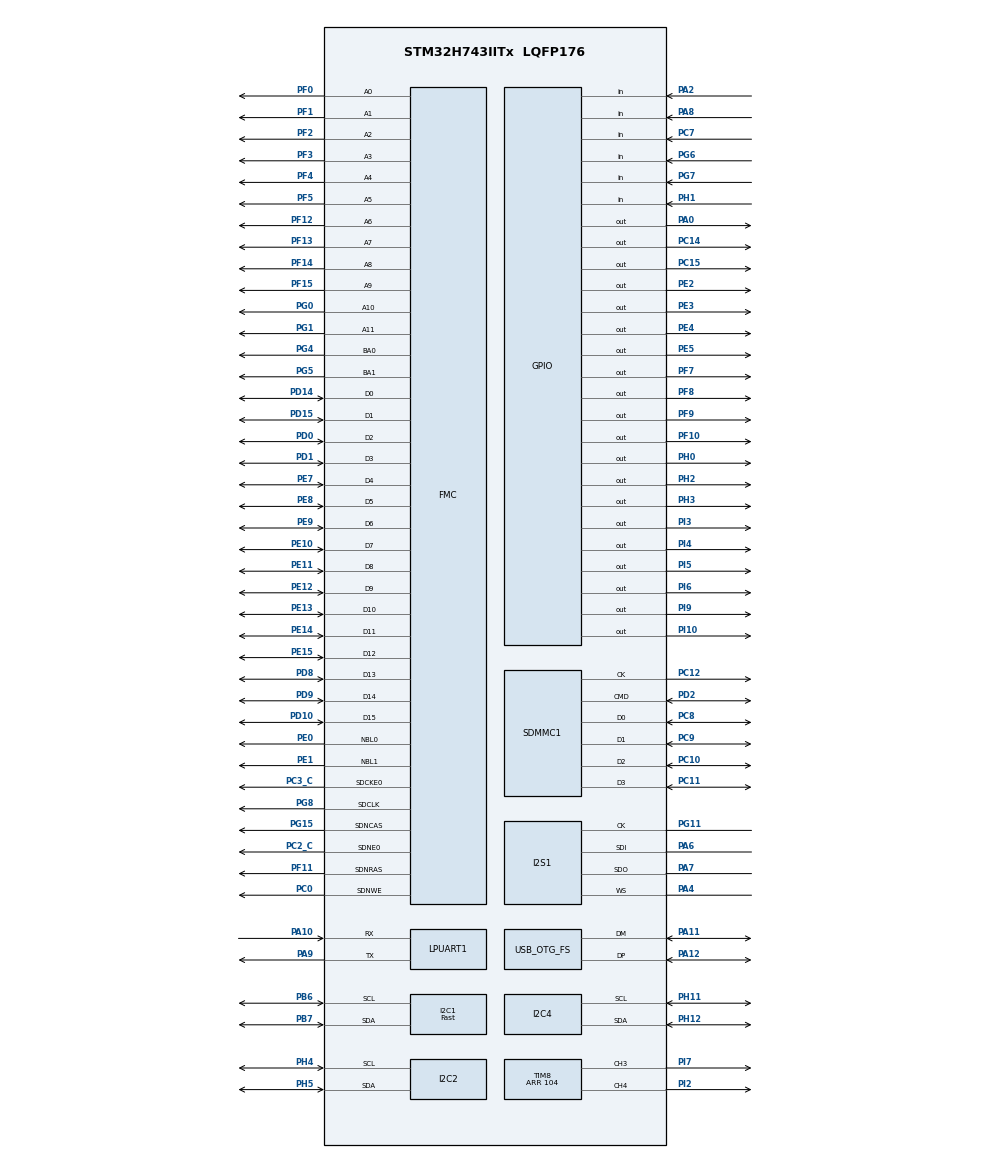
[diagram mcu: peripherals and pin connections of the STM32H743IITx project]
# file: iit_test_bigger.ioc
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CORTEX_M7.default_mode_Activation=1
Dma.Request0=TIM8_CH4
Dma.Request1=TIM8_CH3
Dma.TIM8_CH3.1.Direction=DMA_MEMORY_TO_PERIPH
Dma.TIM8_CH3.1.EventEnable=DISABLE
Dma.TIM8_CH3.1.FIFOMode=DMA_FIFOMODE_DISABLE
Dma.TIM8_CH3.1.Instance=DMA1_Stream1
Dma.TIM8_CH3.1.MemDataAlignment=DMA_MDATAALIGN_HALFWORD
Dma.TIM8_CH3.1.MemInc=DMA_MINC_ENABLE
Dma.TIM8_CH3.1.Mode=DMA_NORMAL
Dma.TIM8_CH3.1.PeriphDataAlignment=DMA_PDATAALIGN_HALFWORD
Dma.TIM8_CH3.1.PeriphInc=DMA_PINC_DISABLE
Dma.TIM8_CH3.1.Polarity=HAL_DMAMUX_REQ_GEN_RISING
Dma.TIM8_CH3.1.Priority=DMA_PRIORITY_HIGH
Dma.TIM8_CH3.1.RequestNumber=1
Dma.TIM8_CH3.1.SignalID=NONE
Dma.TIM8_CH3.1.SyncEnable=DISABLE
Dma.TIM8_CH3.1.SyncPolarity=HAL_DMAMUX_SYNC_NO_EVENT
Dma.TIM8_CH3.1.SyncRequestNumber=1
Dma.TIM8_CH3.1.SyncSignalID=NONE
Dma.TIM8_CH4.0.Direction=DMA_MEMORY_TO_PERIPH
Dma.TIM8_CH4.0.EventEnable=DISABLE
Dma.TIM8_CH4.0.FIFOMode=DMA_FIFOMODE_DISABLE
Dma.TIM8_CH4.0.Instance=DMA1_Stream0
Dma.TIM8_CH4.0.MemDataAlignment=DMA_MDATAALIGN_HALFWORD
Dma.TIM8_CH4.0.MemInc=DMA_MINC_ENABLE
Dma.TIM8_CH4.0.Mode=DMA_NORMAL
Dma.TIM8_CH4.0.PeriphDataAlignment=DMA_PDATAALIGN_HALFWORD
Dma.TIM8_CH4.0.PeriphInc=DMA_PINC_DISABLE
Dma.TIM8_CH4.0.Polarity=HAL_DMAMUX_REQ_GEN_RISING
Dma.TIM8_CH4.0.Priority=DMA_PRIORITY_HIGH
Dma.TIM8_CH4.0.RequestNumber=1
Dma.TIM8_CH4.0.SignalID=NONE
Dma.TIM8_CH4.0.SyncEnable=DISABLE
Dma.TIM8_CH4.0.SyncPolarity=HAL_DMAMUX_SYNC_NO_EVENT
Dma.TIM8_CH4.0.SyncRequestNumber=1
Dma.TIM8_CH4.0.SyncSignalID=NONE
FMC.CASLatency1=FMC_SDRAM_CAS_LATENCY_3
FMC.ColumnBitsNumber1=FMC_SDRAM_COLUMN_BITS_NUM_9
FMC.ExitSelfRefreshDelay1=7
FMC.LoadToActiveDelay1=2
FMC.RCDDelay1=2
FMC.RPDelay1=2
FMC.RPDelay2=2
FMC.ReadBurst1=FMC_SDRAM_RBURST_ENABLE
FMC.ReadPipeDelay1=FMC_SDRAM_RPIPE_DELAY_1
FMC.ReadPipeDelay2=FMC_SDRAM_RPIPE_DELAY_1
FMC.RowCycleDelay1=7
FMC.RowCycleDelay2=7
FMC.SDClockPeriod1=FMC_SDRAM_CLOCK_PERIOD_2
FMC.SelfRefreshTime1=4
FMC.WriteRecoveryTime1=3
I2C1.I2C_Speed_Mode=I2C_Fast
I2C1.Timing=0x00300F38
I2C2.Timing=0x00707CBB
I2C4.Timing=0x00707CBB
I2S1.ErrorAudioFreq=-0.16 %
I2S1.Instance=SPI$Index
I2S1.RealAudioFreq=7.987 KHz
Mcu.Family=STM32H7
Mcu.Name=STM32H743IITx
Mcu.Package=LQFP176
NVIC.DMA1_Stream0_IRQn=true\:0\:0\:false\:false\:true\:false\:true\:true
NVIC.DMA1_Stream1_IRQn=true\:0\:0\:false\:false\:true\:false\:true\:true
NVIC.OTG_FS_IRQn=true\:0\:0\:false\:false\:true\:true\:true\:true
NVIC.PriorityGroup=NVIC_PRIORITYGROUP_4
PA0.Signal=GPIO_Output
PA10.Mode=Asynchronous
PA10.Signal=LPUART1_RX
PA11.Mode=Device_Only
PA11.Signal=USB_OTG_FS_DM
PA12.Mode=Device_Only
PA12.Signal=USB_OTG_FS_DP
PA13\ (JTMS/SWDIO).Mode=Serial_Wire
PA13\ (JTMS/SWDIO).Signal=DEBUG_JTMS-SWDIO
PA14\ (JTCK/SWCLK).Mode=Serial_Wire
PA14\ (JTCK/SWCLK).Signal=DEBUG_JTCK-SWCLK
PA15\ (JTDI).Signal=DEBUG_JTDI
PA2.Signal=GPIO_Input
PA4.Mode=Full_Duplex_Master
PA4.Signal=I2S1_WS
PA6.Mode=Full_Duplex_Master
PA6.Signal=I2S1_SDI
PA7.Mode=Full_Duplex_Master
PA7.Signal=I2S1_SDO
PA8.Signal=GPIO_Input
PA9.Mode=Asynchronous
PA9.Signal=LPUART1_TX
PB3\ (JTDO/TRACESWO).Signal=DEBUG_JTDO-SWO
PB6.Mode=I2C
PB6.Signal=I2C1_SCL
PB7.Mode=I2C
PB7.Signal=I2C1_SDA
PC0.Signal=FMC_SDNWE
PC10.Mode=SD_4_bits_Wide_bus
PC10.Signal=SDMMC1_D2
PC11.Mode=SD_4_bits_Wide_bus
PC11.Signal=SDMMC1_D3
PC12.Mode=SD_4_bits_Wide_bus
PC12.Signal=SDMMC1_CK
PC14-OSC32_IN\ (OSC32_IN).Signal=GPIO_Output
PC15-OSC32_OUT\ (OSC32_OUT).Signal=GPIO_Output
PC2_C.Mode=SdramChipSelect1_1
PC2_C.Signal=FMC_SDNE0
PC3_C.Mode=SdramChipSelect1_1
PC3_C.Signal=FMC_SDCKE0
PC7.Signal=GPIO_Input
PC8.Mode=SD_4_bits_Wide_bus
PC8.Signal=SDMMC1_D0
PC9.Mode=SD_4_bits_Wide_bus
PC9.Signal=SDMMC1_D1
PD0.Signal=FMC_D2_DA2
PD1.Signal=FMC_D3_DA3
PD10.Signal=FMC_D15_DA15
PD14.Signal=FMC_D0_DA0
PD15.Signal=FMC_D1_DA1
PD2.Mode=SD_4_bits_Wide_bus
PD2.Signal=SDMMC1_CMD
PD8.Signal=FMC_D13_DA13
PD9.Signal=FMC_D14_DA14
PE0.Signal=FMC_NBL0
PE1.Signal=FMC_NBL1
PE10.Signal=FMC_D7_DA7
PE11.Signal=FMC_D8_DA8
PE12.Signal=FMC_D9_DA9
PE13.Signal=FMC_D10_DA10
PE14.Signal=FMC_D11_DA11
PE15.Signal=FMC_D12_DA12
PE2.Signal=GPIO_Output
PE3.Signal=GPIO_Output
PE4.Signal=GPIO_Output
PE5.Signal=GPIO_Output
PE7.Signal=FMC_D4_DA4
PE8.Signal=FMC_D5_DA5
PE9.Signal=FMC_D6_DA6
PF0.Signal=FMC_A0
PF1.Signal=FMC_A1
PF10.Signal=GPIO_Output
PF11.Signal=FMC_SDNRAS
PF12.Signal=FMC_A6
PF13.Signal=FMC_A7
PF14.Signal=FMC_A8
PF15.Signal=FMC_A9
PF2.Signal=FMC_A2
PF3.Signal=FMC_A3
PF4.Signal=FMC_A4
PF5.Signal=FMC_A5
PF7.Signal=GPIO_Output
PF8.Signal=GPIO_Output
PF9.Signal=GPIO_Output
PG0.Signal=FMC_A10
PG1.Signal=FMC_A11
PG11.Mode=Full_Duplex_Master
PG11.Signal=I2S1_CK
PG15.Signal=FMC_SDNCAS
PG4.Signal=FMC_A14_BA0
PG5.Signal=FMC_A15_BA1
PG6.Signal=GPIO_Input
PG7.Signal=GPIO_Input
PG8.Signal=FMC_SDCLK
PH0-OSC_IN\ (PH0).Signal=GPIO_Output
PH1-OSC_OUT\ (PH1).Signal=GPIO_Input
PH11.Mode=I2C
PH11.Signal=I2C4_SCL
PH12.Mode=I2C
PH12.Signal=I2C4_SDA
PH2.Signal=GPIO_Output
PH3.Signal=GPIO_Output
PH4.Mode=I2C
PH4.Signal=I2C2_SCL
PH5.Mode=I2C
PH5.Signal=I2C2_SDA
PI10.Signal=GPIO_Output
PI2.Signal=S_TIM8_CH4
PI3.Signal=GPIO_Output
PI4.Signal=GPIO_Output
PI5.Signal=GPIO_Output
PI6.Signal=GPIO_Output
PI7.Signal=S_TIM8_CH3
PI9.Signal=GPIO_Output
ProjectManager.HeapSize=0x200
ProjectManager.StackSize=0x400
ProjectManager.TargetToolchain=CMake
RCC.ADCFreq_Value=128000000
RCC.APB1Freq_Value=32000000
RCC.APB2Freq_Value=64000000
RCC.APB3Freq_Value=32000000
RCC.APB4Freq_Value=32000000
RCC.CortexFreq_Value=64000000
RCC.D1PPRE=RCC_APB3_DIV2
RCC.D2PPRE1=RCC_APB1_DIV2
RCC.D3PPRE=RCC_APB4_DIV2
RCC.DIVM1=4
RCC.DIVM2=4
RCC.DIVN1=25
RCC.DIVN2=16
RCC.DIVQ1=5
RCC.FMCCLockSelection=RCC_FMCCLKSOURCE_PLL2
RCC.HCLKFreq_Value=64000000
RCC.SYSCLKFreq_VALUE=64000000
RCC.USBCLockSelection=RCC_USBCLKSOURCE_HSI48
RCC.USBFreq_Value=48000000
SDMMC1.ClockDiv=2
SH.FMC_A0.0=FMC_A0,12b-sda1
SH.FMC_A1.0=FMC_A1,12b-sda1
SH.FMC_A10.0=FMC_A10,12b-sda1
SH.FMC_A11.0=FMC_A11,12b-sda1
SH.FMC_A14_BA0.0=FMC_BA0,FourSdramBanks1
SH.FMC_A15_BA1.0=FMC_BA1,FourSdramBanks1
SH.FMC_A2.0=FMC_A2,12b-sda1
SH.FMC_A3.0=FMC_A3,12b-sda1
SH.FMC_A4.0=FMC_A4,12b-sda1
SH.FMC_A5.0=FMC_A5,12b-sda1
SH.FMC_A6.0=FMC_A6,12b-sda1
SH.FMC_A7.0=FMC_A7,12b-sda1
SH.FMC_A8.0=FMC_A8,12b-sda1
SH.FMC_A9.0=FMC_A9,12b-sda1
SH.FMC_D0_DA0.0=FMC_D0,sd-16b-d1
SH.FMC_D10_DA10.0=FMC_D10,sd-16b-d1
SH.FMC_D11_DA11.0=FMC_D11,sd-16b-d1
SH.FMC_D12_DA12.0=FMC_D12,sd-16b-d1
SH.FMC_D13_DA13.0=FMC_D13,sd-16b-d1
SH.FMC_D14_DA14.0=FMC_D14,sd-16b-d1
SH.FMC_D15_DA15.0=FMC_D15,sd-16b-d1
SH.FMC_D1_DA1.0=FMC_D1,sd-16b-d1
SH.FMC_D2_DA2.0=FMC_D2,sd-16b-d1
SH.FMC_D3_DA3.0=FMC_D3,sd-16b-d1
SH.FMC_D4_DA4.0=FMC_D4,sd-16b-d1
SH.FMC_D5_DA5.0=FMC_D5,sd-16b-d1
SH.FMC_D6_DA6.0=FMC_D6,sd-16b-d1
SH.FMC_D7_DA7.0=FMC_D7,sd-16b-d1
SH.FMC_D8_DA8.0=FMC_D8,sd-16b-d1
SH.FMC_D9_DA9.0=FMC_D9,sd-16b-d1
SH.FMC_NBL0.0=FMC_NBL0,Sd2ByteEnable1
SH.FMC_NBL1.0=FMC_NBL1,Sd2ByteEnable1
SH.FMC_SDCLK.0=FMC_SDCLK,12b-sda1
SH.FMC_SDNCAS.0=FMC_SDNCAS,12b-sda1
SH.FMC_SDNRAS.0=FMC_SDNRAS,12b-sda1
SH.FMC_SDNWE.0=FMC_SDNWE,12b-sda1
SH.S_TIM8_CH3.0=TIM8_CH3,PWM Generation3 CH3
SH.S_TIM8_CH4.0=TIM8_CH4,PWM Generation4 CH4
TIM8.Channel-PWM\ Generation3\ CH3=TIM_CHANNEL_3
TIM8.Channel-PWM\ Generation4\ CH4=TIM_CHANNEL_4
TIM8.Period=104
USB_OTG_FS.VirtualMode=Device_Only
VP_MEMORYMAP_VS_MEMORYMAP.Mode=CurAppReg
board=custom

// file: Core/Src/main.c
/* USER CODE BEGIN Header */
/**
  ******************************************************************************
  * @file           : main.c
  * @brief          : Main program body
  ******************************************************************************
  * @attention
  *
  * Copyright (c) 2026 STMicroelectronics.
  * All rights reserved.
  *
  * This software is licensed under terms that can be found in the LICENSE file
  * in the root directory of this software component.
  * If no LICENSE file comes with this software, it is provided AS-IS.
  *
  ******************************************************************************
  */
/* USER CODE END Header */
#include "main.h"

/* USER CODE BEGIN Includes */

#include <stdbool.h>
#include <stdint.h>
#include <stdio.h>

#include "stm32h7xx_hal.h"
#include "stm32h7xx_hal_gpio.h"

#include "tusb.h"
#include "helper.h"

#include "neopixel32.h"
#include "TMAG5273.h"
#include "button.h"
#include "tmag-helper.h"
#include "rgb-helper.h"
#include "lcd-helper.h"

#include "midi.h"

/* USER CODE END Includes */

I2C_HandleTypeDef hi2c1;
I2C_HandleTypeDef hi2c2;
I2C_HandleTypeDef hi2c4;

I2S_HandleTypeDef hi2s1;

UART_HandleTypeDef hlpuart1;

SD_HandleTypeDef hsd1;

TIM_HandleTypeDef htim8;
DMA_HandleTypeDef hdma_tim8_ch4;
DMA_HandleTypeDef hdma_tim8_ch3;

PCD_HandleTypeDef hpcd_USB_OTG_FS;

SDRAM_HandleTypeDef hsdram1;

/* USER CODE BEGIN PV */
bool getFirstTick = true;
uint32_t firstTick = 0;
bool probe_resting_pos = true;
/* USER CODE END PV */

void SystemClock_Config(void);
static void MPU_Config(void);
static void MX_GPIO_Init(void);
static void MX_DMA_Init(void);
static void MX_FMC_Init(void);
static void MX_I2C1_Init(void);
static void MX_I2C2_Init(void);
static void MX_I2C4_Init(void);
static void MX_SDMMC1_SD_Init(void);
static void MX_I2S1_Init(void);
static void MX_LPUART1_UART_Init(void);
static void MX_TIM8_Init(void);
static void MX_USB_OTG_FS_PCD_Init(void);

/* USER CODE BEGIN 0 */
void tick_service() {
  if (getFirstTick) {
    getFirstTick = false;
    firstTick = HAL_GetTick();
  }

  //create a delay before storing initial sensor data, let them warm up bro
  if (((HAL_GetTick() - firstTick) > 1000) && probe_resting_pos) {
    probe_resting_pos = false;
    storedInitialData = false;
    animate_led_startup = true;
  }

  if (animate_led_startup) {
    tick_led_animation();
  }

  //after ~2 seconds
  if (((HAL_GetTick() - firstTick) > 2000)) {
    if (!trigger_main_screen) {
      trigger_main_screen = true;
      state = MAIN_MENU;
    }

    ui_service_tick();
  }
}
/* USER CODE END 0 */

int main(void)
{

  /* MPU Configuration--------------------------------------------------------*/
  MPU_Config();

  /* MCU Configuration--------------------------------------------------------*/

  /* Reset of all peripherals, Initializes the Flash interface and the Systick. */
  HAL_Init();

  /* Configure the system clock */
  SystemClock_Config();

  /* Initialize all configured peripherals */
  MX_GPIO_Init();
  MX_DMA_Init();
  MX_FMC_Init();
  MX_I2C1_Init();
  MX_I2C2_Init();
  MX_I2C4_Init();
  MX_SDMMC1_SD_Init();
  MX_I2S1_Init();
  MX_LPUART1_UART_Init();
  MX_TIM8_Init();
  MX_USB_OTG_FS_PCD_Init();
  /* USER CODE BEGIN 2 */

  debugtalk("hello world\r\n");

  // init neopixels --------------------------------------------------------------------------------------------------------------------

  //internal
  neopixel_instance_internal.LED_Count = 6;
  neopixel_instance_internal.StartDMA_Call = Start_LED_DMA;

  if (NP32_Init(&neopixel_instance_internal) != 0) {
    debugtalk("bad0\r\n");
    Error_Handler();
  }

  NP32_SetAllLEDs_RGB(&neopixel_instance_internal, color_black);
  NP32_Update(&neopixel_instance_internal);

  //keys
  neopixel_instance_keys.LED_Count = 24;
  neopixel_instance_keys.StartDMA_Call = Start_LED_DMA_KEYS;

  if (NP32_Init(&neopixel_instance_keys) != 0) {
    debugtalk("bad00\r\n");
    Error_Handler();
  }

  NP32_SetAllLEDs_RGB(&neopixel_instance_keys, color_black);
  NP32_Update(&neopixel_instance_keys);

  // init i2c lcd display --------------------------------------------------------------------------------------------------------------
  //scan all addresses on i2c as some lcd modules use random
  uint16_t lcd_address = probe_i2c_addr(&hi2c4);

  if (HAL_I2C_IsDeviceReady(&hi2c4, lcd_address, 3, 100) != HAL_OK) {
    debugtalk("LCD not found\r\n");
  }

  lcd.hi2c = &hi2c4;
  lcd.address = (uint8_t)lcd_address;
  lcd_init(&lcd);
  lcd_clear(&lcd);

  lcd_puts(&lcd, "welcome to");
  lcd_gotoxy(&lcd, 0, 1);
  lcd_puts(&lcd, "mpe32board.");

  // init i2c muxes 4 sensors ----------------------------------------------------------------------------------------------------------
  // set mp-reset on the i2c mux to be high as it is active-low reset input
	HAL_GPIO_WritePin(GPIOI, GPIO_PIN_3, GPIO_PIN_SET);

  uint8_t mret = HAL_I2C_IsDeviceReady(&hi2c1, 0x70 << 1, 3, 5);
  if (mret != HAL_OK) {
    debugtalk("bad mux1");
  }

  uint8_t mret2 = HAL_I2C_IsDeviceReady(&hi2c1, 0x71 << 1, 3, 5);
  if (mret2 != HAL_OK) {
    debugtalk("bad mux2");
  }

  uint8_t mret3 = HAL_I2C_IsDeviceReady(&hi2c1, 0x72 << 1, 3, 5);
  if (mret3 != HAL_OK) {
    debugtalk("bad mux3");
  }

  // disable all i2c channels for a clean slate bruh
	if (i2c_mux_reset(&tca_mux_1) != 0) {
    debugtalk("bad1\r\n");
    NP32_SetLED_RGB(&neopixel_instance_internal, 0, color_red);
    NP32_Update(&neopixel_instance_internal);
	}

  if (i2c_mux_reset(&tca_mux_2) != 0) {
    debugtalk("bad2\r\n");
    NP32_SetLED_RGB(&neopixel_instance_internal, 1, color_red);
    NP32_Update(&neopixel_instance_internal);
	}

  if (i2c_mux_reset(&tca_mux_3) != 0) {
    debugtalk("bad3\r\n");
    NP32_SetLED_RGB(&neopixel_instance_internal, 0, color_blue);
    NP32_Update(&neopixel_instance_internal);
	}

  Init_TMAGS();

  // init mpe32board device settings/config here ----------------------------------------------------------------------------------------

  storedInitialData = false;
  fill_midi_key_arr(24, octave);

  // init device stack for tiny usb!!! https://docs.tinyusb.org/en/latest/integration.html ----------------------------------------------
	tud_cdc_write_clear();

  if (!tusb_init(BOARD_DEVICE_RHPORT_NUM, NULL)) {
    debugtalk("bad4\r\n");
  }

  /* USER CODE END 2 */

  /* Infinite loop */
  while (1)
  {

    /* USER CODE BEGIN 3 */

    tud_task();

    tick_service();

    //gather button data
    // SWITCH HERE BETWEEN DEVELOPMENT AND PRODUCTION ENVIRONMENTS //TODO
    //button_debug_handle();
    button_handle();

    //gather sensor data
    sensor_handle();

    //parse data to midi
    midi_parse();

    NP32_Update(&neopixel_instance_internal);
    NP32_Update(&neopixel_instance_keys);

  }
  /* USER CODE END 3 */
}

void SystemClock_Config(void)
{
  RCC_OscInitTypeDef RCC_OscInitStruct = {0};
  RCC_ClkInitTypeDef RCC_ClkInitStruct = {0};

  /** Supply configuration update enable
  */
  HAL_PWREx_ConfigSupply(PWR_LDO_SUPPLY);

  /** Configure the main internal regulator output voltage
  */
  __HAL_PWR_VOLTAGESCALING_CONFIG(PWR_REGULATOR_VOLTAGE_SCALE3);

  while(!__HAL_PWR_GET_FLAG(PWR_FLAG_VOSRDY)) {}

  /** Initializes the RCC Oscillators according to the specified parameters
  * in the RCC_OscInitTypeDef structure.
  */
  RCC_OscInitStruct.OscillatorType = RCC_OSCILLATORTYPE_HSI48|RCC_OSCILLATORTYPE_HSI;
  RCC_OscInitStruct.HSIState = RCC_HSI_DIV1;
  RCC_OscInitStruct.HSICalibrationValue = RCC_HSICALIBRATION_DEFAULT;
  RCC_OscInitStruct.HSI48State = RCC_HSI48_ON;
  RCC_OscInitStruct.PLL.PLLState = RCC_PLL_ON;
  RCC_OscInitStruct.PLL.PLLSource = RCC_PLLSOURCE_HSI;
  RCC_OscInitStruct.PLL.PLLM = 4;
  RCC_OscInitStruct.PLL.PLLN = 25;
  RCC_OscInitStruct.PLL.PLLP = 2;
  RCC_OscInitStruct.PLL.PLLQ = 5;
  RCC_OscInitStruct.PLL.PLLR = 2;
  RCC_OscInitStruct.PLL.PLLRGE = RCC_PLL1VCIRANGE_3;
  RCC_OscInitStruct.PLL.PLLVCOSEL = RCC_PLL1VCOWIDE;
  RCC_OscInitStruct.PLL.PLLFRACN = 0;
  if (HAL_RCC_OscConfig(&RCC_OscInitStruct) != HAL_OK)
  {
    Error_Handler();
  }

  /** Initializes the CPU, AHB and APB buses clocks
  */
  RCC_ClkInitStruct.ClockType = RCC_CLOCKTYPE_HCLK|RCC_CLOCKTYPE_SYSCLK
                              |RCC_CLOCKTYPE_PCLK1|RCC_CLOCKTYPE_PCLK2
                              |RCC_CLOCKTYPE_D3PCLK1|RCC_CLOCKTYPE_D1PCLK1;
  RCC_ClkInitStruct.SYSCLKSource = RCC_SYSCLKSOURCE_HSI;
  RCC_ClkInitStruct.SYSCLKDivider = RCC_SYSCLK_DIV1;
  RCC_ClkInitStruct.AHBCLKDivider = RCC_HCLK_DIV1;
  RCC_ClkInitStruct.APB3CLKDivider = RCC_APB3_DIV2;
  RCC_ClkInitStruct.APB1CLKDivider = RCC_APB1_DIV2;
  RCC_ClkInitStruct.APB2CLKDivider = RCC_APB2_DIV1;
  RCC_ClkInitStruct.APB4CLKDivider = RCC_APB4_DIV2;

  if (HAL_RCC_ClockConfig(&RCC_ClkInitStruct, FLASH_LATENCY_1) != HAL_OK)
  {
    Error_Handler();
  }
}

static void MX_I2C1_Init(void)
{

  hi2c1.Instance = I2C1;
  hi2c1.Init.Timing = 0x00300F38;
  hi2c1.Init.OwnAddress1 = 0;
  hi2c1.Init.AddressingMode = I2C_ADDRESSINGMODE_7BIT;
  hi2c1.Init.DualAddressMode = I2C_DUALADDRESS_DISABLE;
  hi2c1.Init.OwnAddress2 = 0;
  hi2c1.Init.OwnAddress2Masks = I2C_OA2_NOMASK;
  hi2c1.Init.GeneralCallMode = I2C_GENERALCALL_DISABLE;
  hi2c1.Init.NoStretchMode = I2C_NOSTRETCH_DISABLE;
  if (HAL_I2C_Init(&hi2c1) != HAL_OK)
  {
    Error_Handler();
  }

  /** Configure Analogue filter
  */
  if (HAL_I2CEx_ConfigAnalogFilter(&hi2c1, I2C_ANALOGFILTER_ENABLE) != HAL_OK)
  {
    Error_Handler();
  }

  /** Configure Digital filter
  */
  if (HAL_I2CEx_ConfigDigitalFilter(&hi2c1, 0) != HAL_OK)
  {
    Error_Handler();
  }

}

static void MX_I2C2_Init(void)
{

  hi2c2.Instance = I2C2;
  hi2c2.Init.Timing = 0x00707CBB;
  hi2c2.Init.OwnAddress1 = 0;
  hi2c2.Init.AddressingMode = I2C_ADDRESSINGMODE_7BIT;
  hi2c2.Init.DualAddressMode = I2C_DUALADDRESS_DISABLE;
  hi2c2.Init.OwnAddress2 = 0;
  hi2c2.Init.OwnAddress2Masks = I2C_OA2_NOMASK;
  hi2c2.Init.GeneralCallMode = I2C_GENERALCALL_DISABLE;
  hi2c2.Init.NoStretchMode = I2C_NOSTRETCH_DISABLE;
  if (HAL_I2C_Init(&hi2c2) != HAL_OK)
  {
    Error_Handler();
  }

  /** Configure Analogue filter
  */
  if (HAL_I2CEx_ConfigAnalogFilter(&hi2c2, I2C_ANALOGFILTER_ENABLE) != HAL_OK)
  {
    Error_Handler();
  }

  /** Configure Digital filter
  */
  if (HAL_I2CEx_ConfigDigitalFilter(&hi2c2, 0) != HAL_OK)
  {
    Error_Handler();
  }

}

static void MX_I2C4_Init(void)
{

  hi2c4.Instance = I2C4;
  hi2c4.Init.Timing = 0x00707CBB;
  hi2c4.Init.OwnAddress1 = 0;
  hi2c4.Init.AddressingMode = I2C_ADDRESSINGMODE_7BIT;
  hi2c4.Init.DualAddressMode = I2C_DUALADDRESS_DISABLE;
  hi2c4.Init.OwnAddress2 = 0;
  hi2c4.Init.OwnAddress2Masks = I2C_OA2_NOMASK;
  hi2c4.Init.GeneralCallMode = I2C_GENERALCALL_DISABLE;
  hi2c4.Init.NoStretchMode = I2C_NOSTRETCH_DISABLE;
  if (HAL_I2C_Init(&hi2c4) != HAL_OK)
  {
    Error_Handler();
  }

  /** Configure Analogue filter
  */
  if (HAL_I2CEx_ConfigAnalogFilter(&hi2c4, I2C_ANALOGFILTER_ENABLE) != HAL_OK)
  {
    Error_Handler();
  }

  /** Configure Digital filter
  */
  if (HAL_I2CEx_ConfigDigitalFilter(&hi2c4, 0) != HAL_OK)
  {
    Error_Handler();
  }

}

static void MX_I2S1_Init(void)
{

  hi2s1.Instance = SPI1;
  hi2s1.Init.Mode = I2S_MODE_MASTER_FULLDUPLEX;
  hi2s1.Init.Standard = I2S_STANDARD_PHILIPS;
  hi2s1.Init.DataFormat = I2S_DATAFORMAT_16B;
  hi2s1.Init.MCLKOutput = I2S_MCLKOUTPUT_DISABLE;
  hi2s1.Init.AudioFreq = I2S_AUDIOFREQ_8K;
  hi2s1.Init.CPOL = I2S_CPOL_LOW;
  hi2s1.Init.FirstBit = I2S_FIRSTBIT_MSB;
  hi2s1.Init.WSInversion = I2S_WS_INVERSION_DISABLE;
  hi2s1.Init.Data24BitAlignment = I2S_DATA_24BIT_ALIGNMENT_RIGHT;
  hi2s1.Init.MasterKeepIOState = I2S_MASTER_KEEP_IO_STATE_DISABLE;
  if (HAL_I2S_Init(&hi2s1) != HAL_OK)
  {
    Error_Handler();
  }

}

static void MX_LPUART1_UART_Init(void)
{

  hlpuart1.Instance = LPUART1;
  hlpuart1.Init.BaudRate = 209700;
  hlpuart1.Init.WordLength = UART_WORDLENGTH_8B;
  hlpuart1.Init.StopBits = UART_STOPBITS_1;
  hlpuart1.Init.Parity = UART_PARITY_NONE;
  hlpuart1.Init.Mode = UART_MODE_TX_RX;
  hlpuart1.Init.HwFlowCtl = UART_HWCONTROL_NONE;
  hlpuart1.Init.OneBitSampling = UART_ONE_BIT_SAMPLE_DISABLE;
  hlpuart1.Init.ClockPrescaler = UART_PRESCALER_DIV1;
  hlpuart1.AdvancedInit.AdvFeatureInit = UART_ADVFEATURE_NO_INIT;
  hlpuart1.FifoMode = UART_FIFOMODE_DISABLE;
  if (HAL_UART_Init(&hlpuart1) != HAL_OK)
  {
    Error_Handler();
  }
  if (HAL_UARTEx_SetTxFifoThreshold(&hlpuart1, UART_TXFIFO_THRESHOLD_1_8) != HAL_OK)
  {
    Error_Handler();
  }
  if (HAL_UARTEx_SetRxFifoThreshold(&hlpuart1, UART_RXFIFO_THRESHOLD_1_8) != HAL_OK)
  {
    Error_Handler();
  }
  if (HAL_UARTEx_DisableFifoMode(&hlpuart1) != HAL_OK)
  {
    Error_Handler();
  }

}

static void MX_SDMMC1_SD_Init(void)
{

  /* USER CODE BEGIN SDMMC1_Init 1 */

  if (!HAL_GPIO_ReadPin(GPIOH, GPIO_PIN_1)) {
    return;
  }

  __HAL_RCC_SDMMC1_FORCE_RESET();
  __HAL_RCC_SDMMC1_RELEASE_RESET();

  /* USER CODE END SDMMC1_Init 1 */
  hsd1.Instance = SDMMC1;
  hsd1.Init.ClockEdge = SDMMC_CLOCK_EDGE_RISING;
  hsd1.Init.ClockPowerSave = SDMMC_CLOCK_POWER_SAVE_DISABLE;
  hsd1.Init.BusWide = SDMMC_BUS_WIDE_4B;
  hsd1.Init.HardwareFlowControl = SDMMC_HARDWARE_FLOW_CONTROL_DISABLE;
  hsd1.Init.ClockDiv = 2;
  if (HAL_SD_Init(&hsd1) != HAL_OK)
  {
    Error_Handler();
  }

}

static void MX_TIM8_Init(void)
{

  TIM_MasterConfigTypeDef sMasterConfig = {0};
  TIM_OC_InitTypeDef sConfigOC = {0};
  TIM_BreakDeadTimeConfigTypeDef sBreakDeadTimeConfig = {0};

  htim8.Instance = TIM8;
  htim8.Init.Prescaler = 0;
  htim8.Init.CounterMode = TIM_COUNTERMODE_UP;
  htim8.Init.Period = 104;
  htim8.Init.ClockDivision = TIM_CLOCKDIVISION_DIV1;
  htim8.Init.RepetitionCounter = 0;
  htim8.Init.AutoReloadPreload = TIM_AUTORELOAD_PRELOAD_DISABLE;
  if (HAL_TIM_PWM_Init(&htim8) != HAL_OK)
  {
    Error_Handler();
  }
  sMasterConfig.MasterOutputTrigger = TIM_TRGO_RESET;
  sMasterConfig.MasterOutputTrigger2 = TIM_TRGO2_RESET;
  sMasterConfig.MasterSlaveMode = TIM_MASTERSLAVEMODE_DISABLE;
  if (HAL_TIMEx_MasterConfigSynchronization(&htim8, &sMasterConfig) != HAL_OK)
  {
    Error_Handler();
  }
  sConfigOC.OCMode = TIM_OCMODE_PWM1;
  sConfigOC.Pulse = 0;
  sConfigOC.OCPolarity = TIM_OCPOLARITY_HIGH;
  sConfigOC.OCNPolarity = TIM_OCNPOLARITY_HIGH;
  sConfigOC.OCFastMode = TIM_OCFAST_DISABLE;
  sConfigOC.OCIdleState = TIM_OCIDLESTATE_RESET;
  sConfigOC.OCNIdleState = TIM_OCNIDLESTATE_RESET;
  if (HAL_TIM_PWM_ConfigChannel(&htim8, &sConfigOC, TIM_CHANNEL_3) != HAL_OK)
  {
    Error_Handler();
  }
  if (HAL_TIM_PWM_ConfigChannel(&htim8, &sConfigOC, TIM_CHANNEL_4) != HAL_OK)
  {
    Error_Handler();
  }
  sBreakDeadTimeConfig.OffStateRunMode = TIM_OSSR_DISABLE;
  sBreakDeadTimeConfig.OffStateIDLEMode = TIM_OSSI_DISABLE;
  sBreakDeadTimeConfig.LockLevel = TIM_LOCKLEVEL_OFF;
  sBreakDeadTimeConfig.DeadTime = 0;
  sBreakDeadTimeConfig.BreakState = TIM_BREAK_DISABLE;
  sBreakDeadTimeConfig.BreakPolarity = TIM_BREAKPOLARITY_HIGH;
  sBreakDeadTimeConfig.BreakFilter = 0;
  sBreakDeadTimeConfig.Break2State = TIM_BREAK2_DISABLE;
  sBreakDeadTimeConfig.Break2Polarity = TIM_BREAK2POLARITY_HIGH;
  sBreakDeadTimeConfig.Break2Filter = 0;
  sBreakDeadTimeConfig.AutomaticOutput = TIM_AUTOMATICOUTPUT_DISABLE;
  if (HAL_TIMEx_ConfigBreakDeadTime(&htim8, &sBreakDeadTimeConfig) != HAL_OK)
  {
    Error_Handler();
  }
  HAL_TIM_MspPostInit(&htim8);

}

static void MX_USB_OTG_FS_PCD_Init(void)
{

  hpcd_USB_OTG_FS.Instance = USB_OTG_FS;
  hpcd_USB_OTG_FS.Init.dev_endpoints = 9;
  hpcd_USB_OTG_FS.Init.speed = PCD_SPEED_FULL;
  hpcd_USB_OTG_FS.Init.dma_enable = DISABLE;
  hpcd_USB_OTG_FS.Init.phy_itface = PCD_PHY_EMBEDDED;
  hpcd_USB_OTG_FS.Init.Sof_enable = DISABLE;
  hpcd_USB_OTG_FS.Init.low_power_enable = DISABLE;
  hpcd_USB_OTG_FS.Init.lpm_enable = DISABLE;
  hpcd_USB_OTG_FS.Init.battery_charging_enable = DISABLE;
  hpcd_USB_OTG_FS.Init.vbus_sensing_enable = DISABLE;
  hpcd_USB_OTG_FS.Init.use_dedicated_ep1 = DISABLE;
  if (HAL_PCD_Init(&hpcd_USB_OTG_FS) != HAL_OK)
  {
    Error_Handler();
  }

}

static void MX_DMA_Init(void)
{

  /* DMA controller clock enable */
  __HAL_RCC_DMA1_CLK_ENABLE();

  /* DMA interrupt init */
  /* DMA1_Stream0_IRQn interrupt configuration */
  HAL_NVIC_SetPriority(DMA1_Stream0_IRQn, 0, 0);
  HAL_NVIC_EnableIRQ(DMA1_Stream0_IRQn);
  /* DMA1_Stream1_IRQn interrupt configuration */
  HAL_NVIC_SetPriority(DMA1_Stream1_IRQn, 0, 0);
  HAL_NVIC_EnableIRQ(DMA1_Stream1_IRQn);

}

/* FMC initialization function */
static void MX_FMC_Init(void)
{

  FMC_SDRAM_TimingTypeDef SdramTiming = {0};

  /** Perform the SDRAM1 memory initialization sequence
  */
  hsdram1.Instance = FMC_SDRAM_DEVICE;
  /* hsdram1.Init */
  hsdram1.Init.SDBank = FMC_SDRAM_BANK1;
  hsdram1.Init.ColumnBitsNumber = FMC_SDRAM_COLUMN_BITS_NUM_9;
  hsdram1.Init.RowBitsNumber = FMC_SDRAM_ROW_BITS_NUM_12;
  hsdram1.Init.MemoryDataWidth = FMC_SDRAM_MEM_BUS_WIDTH_16;
  hsdram1.Init.InternalBankNumber = FMC_SDRAM_INTERN_BANKS_NUM_4;
  hsdram1.Init.CASLatency = FMC_SDRAM_CAS_LATENCY_3;
  hsdram1.Init.WriteProtection = FMC_SDRAM_WRITE_PROTECTION_DISABLE;
  hsdram1.Init.SDClockPeriod = FMC_SDRAM_CLOCK_PERIOD_2;
  hsdram1.Init.ReadBurst = FMC_SDRAM_RBURST_ENABLE;
  hsdram1.Init.ReadPipeDelay = FMC_SDRAM_RPIPE_DELAY_1;
  /* SdramTiming */
  SdramTiming.LoadToActiveDelay = 2;
  SdramTiming.ExitSelfRefreshDelay = 7;
  SdramTiming.SelfRefreshTime = 4;
  SdramTiming.RowCycleDelay = 7;
  SdramTiming.WriteRecoveryTime = 3;
  SdramTiming.RPDelay = 2;
  SdramTiming.RCDDelay = 2;

  if (HAL_SDRAM_Init(&hsdram1, &SdramTiming) != HAL_OK)
  {
    Error_Handler( );
  }

}

static void MX_GPIO_Init(void)
{
  GPIO_InitTypeDef GPIO_InitStruct = {0};

  /* GPIO Ports Clock Enable */
  __HAL_RCC_GPIOE_CLK_ENABLE();
  __HAL_RCC_GPIOC_CLK_ENABLE();
  __HAL_RCC_GPIOI_CLK_ENABLE();
  __HAL_RCC_GPIOF_CLK_ENABLE();
  __HAL_RCC_GPIOH_CLK_ENABLE();
  __HAL_RCC_GPIOA_CLK_ENABLE();
  __HAL_RCC_GPIOG_CLK_ENABLE();
  __HAL_RCC_GPIOD_CLK_ENABLE();
  __HAL_RCC_GPIOB_CLK_ENABLE();

  /*Configure GPIO pin Output Level */
  HAL_GPIO_WritePin(GPIOE, GPIO_PIN_2|GPIO_PIN_3|GPIO_PIN_4|GPIO_PIN_5, GPIO_PIN_RESET);

  /*Configure GPIO pin Output Level */
  HAL_GPIO_WritePin(GPIOC, GPIO_PIN_14|GPIO_PIN_15, GPIO_PIN_RESET);

  /*Configure GPIO pin Output Level */
  HAL_GPIO_WritePin(GPIOI, GPIO_PIN_9|GPIO_PIN_10|GPIO_PIN_3|GPIO_PIN_4
                          |GPIO_PIN_5|GPIO_PIN_6, GPIO_PIN_RESET);

  /*Configure GPIO pin Output Level */
  HAL_GPIO_WritePin(GPIOF, GPIO_PIN_7|GPIO_PIN_8|GPIO_PIN_9|GPIO_PIN_10, GPIO_PIN_RESET);

  /*Configure GPIO pin Output Level */
  HAL_GPIO_WritePin(GPIOH, GPIO_PIN_0|GPIO_PIN_2|GPIO_PIN_3, GPIO_PIN_RESET);

  /*Configure GPIO pin Output Level */
  HAL_GPIO_WritePin(GPIOA, GPIO_PIN_0, GPIO_PIN_RESET);

  /*Configure GPIO pins : PE2 PE3 PE4 PE5 */
  GPIO_InitStruct.Pin = GPIO_PIN_2|GPIO_PIN_3|GPIO_PIN_4|GPIO_PIN_5;
  GPIO_InitStruct.Mode = GPIO_MODE_OUTPUT_PP;
  GPIO_InitStruct.Pull = GPIO_NOPULL;
  GPIO_InitStruct.Speed = GPIO_SPEED_FREQ_LOW;
  HAL_GPIO_Init(GPIOE, &GPIO_InitStruct);

  /*Configure GPIO pins : PC14 PC15 */
  GPIO_InitStruct.Pin = GPIO_PIN_14|GPIO_PIN_15;
  GPIO_InitStruct.Mode = GPIO_MODE_OUTPUT_PP;
  GPIO_InitStruct.Pull = GPIO_NOPULL;
  GPIO_InitStruct.Speed = GPIO_SPEED_FREQ_LOW;
  HAL_GPIO_Init(GPIOC, &GPIO_InitStruct);

  /*Configure GPIO pins : PI9 PI10 PI3 PI4
                           PI5 PI6 */
  GPIO_InitStruct.Pin = GPIO_PIN_9|GPIO_PIN_10|GPIO_PIN_3|GPIO_PIN_4
                          |GPIO_PIN_5|GPIO_PIN_6;
  GPIO_InitStruct.Mode = GPIO_MODE_OUTPUT_PP;
  GPIO_InitStruct.Pull = GPIO_NOPULL;
  GPIO_InitStruct.Speed = GPIO_SPEED_FREQ_LOW;
  HAL_GPIO_Init(GPIOI, &GPIO_InitStruct);

  /*Configure GPIO pins : PF7 PF8 PF9 PF10 */
  GPIO_InitStruct.Pin = GPIO_PIN_7|GPIO_PIN_8|GPIO_PIN_9|GPIO_PIN_10;
  GPIO_InitStruct.Mode = GPIO_MODE_OUTPUT_PP;
  GPIO_InitStruct.Pull = GPIO_NOPULL;
  GPIO_InitStruct.Speed = GPIO_SPEED_FREQ_LOW;
  HAL_GPIO_Init(GPIOF, &GPIO_InitStruct);

  /*Configure GPIO pins : PH0 PH2 PH3 */
  GPIO_InitStruct.Pin = GPIO_PIN_0|GPIO_PIN_2|GPIO_PIN_3;
  GPIO_InitStruct.Mode = GPIO_MODE_OUTPUT_PP;
  GPIO_InitStruct.Pull = GPIO_NOPULL;
  GPIO_InitStruct.Speed = GPIO_SPEED_FREQ_LOW;
  HAL_GPIO_Init(GPIOH, &GPIO_InitStruct);

  /*Configure GPIO pin : PH1 */
  GPIO_InitStruct.Pin = GPIO_PIN_1;
  GPIO_InitStruct.Mode = GPIO_MODE_INPUT;
  GPIO_InitStruct.Pull = GPIO_NOPULL;
  HAL_GPIO_Init(GPIOH, &GPIO_InitStruct);

  /*Configure GPIO pin : PA0 */
  GPIO_InitStruct.Pin = GPIO_PIN_0;
  GPIO_InitStruct.Mode = GPIO_MODE_OUTPUT_PP;
  GPIO_InitStruct.Pull = GPIO_NOPULL;
  GPIO_InitStruct.Speed = GPIO_SPEED_FREQ_LOW;
  HAL_GPIO_Init(GPIOA, &GPIO_InitStruct);

  /*Configure GPIO pins : PA2 PA8 */
  GPIO_InitStruct.Pin = GPIO_PIN_2|GPIO_PIN_8;
  GPIO_InitStruct.Mode = GPIO_MODE_INPUT;
  GPIO_InitStruct.Pull = GPIO_NOPULL;
  HAL_GPIO_Init(GPIOA, &GPIO_InitStruct);

  /*Configure GPIO pins : PG6 PG7 */
  GPIO_InitStruct.Pin = GPIO_PIN_6|GPIO_PIN_7;
  GPIO_InitStruct.Mode = GPIO_MODE_INPUT;
  GPIO_InitStruct.Pull = GPIO_NOPULL;
  HAL_GPIO_Init(GPIOG, &GPIO_InitStruct);

  /*Configure GPIO pin : PC7 */
  GPIO_InitStruct.Pin = GPIO_PIN_7;
  GPIO_InitStruct.Mode = GPIO_MODE_INPUT;
  GPIO_InitStruct.Pull = GPIO_NOPULL;
  HAL_GPIO_Init(GPIOC, &GPIO_InitStruct);

  /*AnalogSwitch Config */
  HAL_SYSCFG_AnalogSwitchConfig(SYSCFG_SWITCH_PA0, SYSCFG_SWITCH_PA0_CLOSE);

}

 /* MPU Configuration */

void MPU_Config(void)
{
  MPU_Region_InitTypeDef MPU_InitStruct = {0};

  /* Disables the MPU */
  HAL_MPU_Disable();

  /** Initializes and configures the Region and the memory to be protected
  */
  MPU_InitStruct.Enable = MPU_REGION_ENABLE;
  MPU_InitStruct.Number = MPU_REGION_NUMBER0;
  MPU_InitStruct.BaseAddress = 0x0;
  MPU_InitStruct.Size = MPU_REGION_SIZE_4GB;
  MPU_InitStruct.SubRegionDisable = 0x87;
  MPU_InitStruct.TypeExtField = MPU_TEX_LEVEL0;
  MPU_InitStruct.AccessPermission = MPU_REGION_NO_ACCESS;
  MPU_InitStruct.DisableExec = MPU_INSTRUCTION_ACCESS_DISABLE;
  MPU_InitStruct.IsShareable = MPU_ACCESS_SHAREABLE;
  MPU_InitStruct.IsCacheable = MPU_ACCESS_NOT_CACHEABLE;
  MPU_InitStruct.IsBufferable = MPU_ACCESS_NOT_BUFFERABLE;

  HAL_MPU_ConfigRegion(&MPU_InitStruct);
  /* Enables the MPU */
  HAL_MPU_Enable(MPU_PRIVILEGED_DEFAULT);

}

void Error_Handler(void)
{
  __disable_irq();
  while (1)
  {
  }
}
